VERSION ""

NS_ :

BS_:

BO_ 129 steering: 8 ElectricPowerSteering
 SG_ SteeringAngle : 23|16@0- (1,0) [0|0] "deg" Vector__XXX

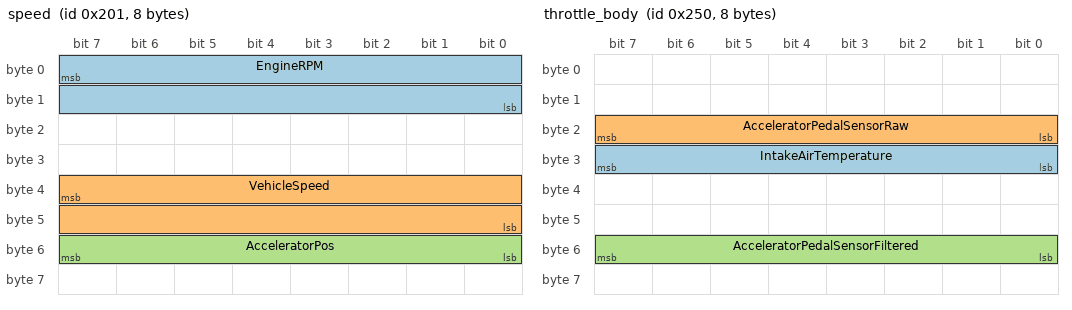
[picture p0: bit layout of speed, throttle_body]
BO_ 513 speed: 8 PowertrainControlModule
 SG_ EngineRPM : 7|16@0+ (0.25,0) [0|0] "rpm" Vector__XXX
 SG_ VehicleSpeed : 39|16@0+ (0.01,-100) [0|0] "kph" Vector__XXX
 SG_ AcceleratorPos : 55|8@0+ (0.5,0) [0|0] "%" Vector__XXX

BO_ 592 throttle_body: 8 PowertrainControlModule
 SG_ IntakeAirTemperature : 31|8@0+ (1,-40) [0|0] "Cel" Vector__XXX
 SG_ AcceleratorPedalSensorRaw : 23|8@0+ (1,0) [0|0] "" Vector__XXX
 SG_ AcceleratorPedalSensorFiltered : 55|8@0+ (1,0) [0|0] "" Vector__XXX

BO_ 658 brake_controls: 8 PowertrainControlModule
 SG_ BrakePedalSwitch : 43|1@1+ (1,0) [0|0] "" Vector__XXX
 SG_ ParkingBrakeSwitch : 38|1@1+ (1,0) [0|0] "" Vector__XXX

BO_ 1056 coolant: 8 PowertrainControlModule
 SG_ CoolantTemperature : 7|8@0+ (1,-40) [0|0] "Cel" Vector__XXX

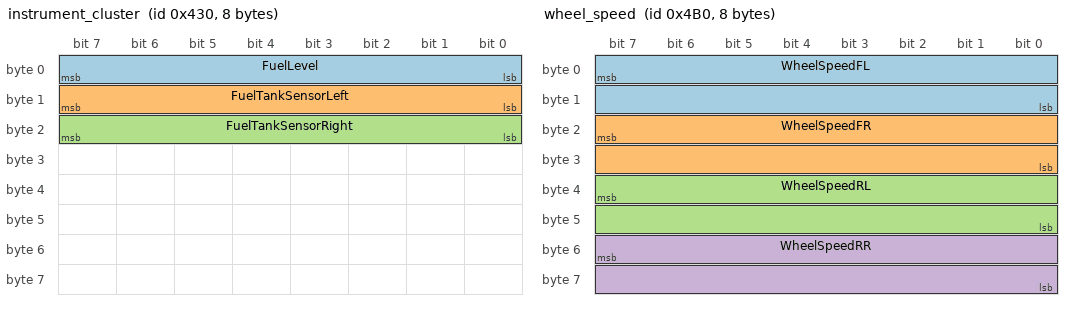
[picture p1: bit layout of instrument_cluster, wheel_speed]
BO_ 1072 instrument_cluster: 8 InstrumentCluster
 SG_ FuelLevel : 7|8@0+ (0.392156,0) [0|0] "%" Vector__XXX
 SG_ FuelTankSensorLeft : 15|8@0+ (1,0) [0|0] "" Vector__XXX
 SG_ FuelTankSensorRight : 23|8@0+ (1,0) [0|0] "" Vector__XXX

BO_ 1200 wheel_speed: 8 AntilockBrakeSystem
 SG_ WheelSpeedFL : 7|16@0+ (0.01,-100) [0|0] "kph" Vector__XXX
 SG_ WheelSpeedFR : 23|16@0+ (0.01,-100) [0|0] "kph" Vector__XXX
 SG_ WheelSpeedRL : 39|16@0+ (0.01,-100) [0|0] "kph" Vector__XXX
 SG_ WheelSpeedRR : 55|16@0+ (0.01,-100) [0|0] "kph" Vector__XXX

BU_: Airbag_MQB BAP_Tester_MQB BMS_MQB Datenlogger_MQB Gateway_MQB Getriebe_DQ_Hybrid_MQB Getriebe_DQ_MQB LEH_MQB Motor_Diesel_MQB Motor_Hybrid_MQB Motor_Otto_MQB SAK_MQB Waehlhebel_MQB Vector__XXX l c i XXX

CM_ "AUTOGENERATED FILE, DO NOT EDIT";

CM_ "Imported file _honda_common.dbc starts here";
CM_ SG_ 304 "Seems to be platform-agnostic";
CM_ SG_ 316 "Should exist on Nidec";
CM_ SG_ 420 BRAKE_HOLD_RELATED "On when Brake Hold engaged";
CM_ SG_ 490 LONG_ACCEL "wheel speed derivative, noisy and zero snapping";
CM_ SG_ 773 PASS_AIRBAG_ON "Might just be indicator light";
CM_ SG_ 773 PASS_AIRBAG_OFF "Might just be indicator light";
CM_ SG_ 780 CRUISE_SPEED "255 = no speed";
CM_ SG_ 780 PCM_SPEED "Used by Nidec";
CM_ SG_ 780 PCM_GAS "Used by Nidec";
CM_ SG_ 804 CRUISE_SPEED_PCM "255 = no speed";

CM_ "Imported file _bosch_2018.dbc starts here";
CM_ SG_ 450 EPB_STATE "3: On, 2: Disengaging, 1: Engaging, 0: Off";
CM_ SG_ 576 LINE_DISTANCE_VISIBLE "Length of line visible, undecoded";
CM_ SG_ 577 LINE_FAR_EDGE_POSITION "Appears to be a measure of line thickness, indicates location of the portion of the line furthest from the car, undecoded";
CM_ SG_ 577 LINE_PARAMETER "Unclear if this is low quality line curvature rate or if this is something else, but it is correlated with line curvature, undecoded";
CM_ SG_ 577 LINE_DASHED "1 = line is dashed";
CM_ SG_ 577 LINE_SOLID "1 = line is solid";

CM_ "Imported file _bosch_adas_2018.dbc starts here";
CM_ SG_ 479 CONTROL_ON "Set to 5 when car is being controlled";
CM_ SG_ 479 AEB_STATUS "set for the duration of AEB event";
CM_ SG_ 479 AEB_BRAKING "set when braking is commanded during AEB event";
CM_ SG_ 479 AEB_PREPARE "set 1s before AEB";
CM_ SG_ 829 BEEP "beeps are pleasant, chimes are for warnngs etc...";

CM_ "Imported file _steering_sensors_a.dbc starts here";
CM_ "honda_crv_ex_2017_can.dbc starts here";

CM_ SG_ 479 RELATED_TO_GAS "bits 7, 3, and 1 set to 1 when gas not applied";
CM_ SG_ 479 GAS_BRAKE "Signed value, negative when braking and positive when applying gas";
